# CH564 register map
Vendor: WCH Ltd.; File version: 1.0
Registers are 8-bit, read-write, reset 0x0 unless marked. A register's access mark holds for its fields unless they carry their own. Offsets are from the block's base; [hi:lo] are bit positions.

## SPI1
Base 0x4040C800
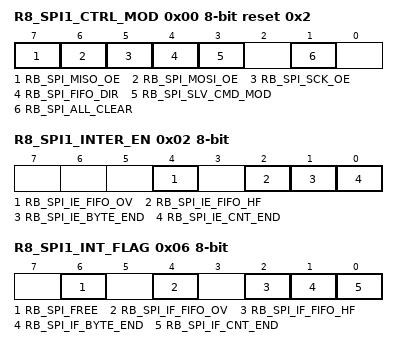
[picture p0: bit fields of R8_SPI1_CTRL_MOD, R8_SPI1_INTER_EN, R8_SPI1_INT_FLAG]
0x00 R8_SPI1_CTRL_MOD reset 0x2 — SPI1 mode control
  [7] RB_SPI_MISO_OE — SPI 2 wire or 3 wire SPI mode configuration bits
  [6] RB_SPI_MOSI_OE — SPI MOSI output enable
  [5] RB_SPI_SCK_OE — SPI SCK output enable
  [4] RB_SPI_FIFO_DIR — SPI FIFO direction
  [3] RB_SPI_SLV_CMD_MOD — SPI slave command mode
  [1] RB_SPI_ALL_CLEAR — force clear SPI FIFO and count
0x01 R8_SPI1_CTRL_DMA — SPI1 DMA control
  [7] RB_SPI_HS_HOST — High speed host receive mode control bit
0x02 R8_SPI1_INTER_EN — SPI1 interrupt enable
  [4] RB_SPI_IE_FIFO_OV — enable interrupt for SPI FIFO overflow
  [2] RB_SPI_IE_FIFO_HF — enable interrupt for SPI FIFO half
  [1] RB_SPI_IE_BYTE_END — enable interrupt for SPI single byte exchanged
  [0] RB_SPI_IE_CNT_END — enable interrupt for SPI total byte count end
0x03 R8_SPI1_CLOCK_DIV reset 0x2 — SPI1 master clock divisor
  [7:0] SPI1_CLOCK_DIV — master clock divisor
0x04 R8_SPI1_BUFFER — SPI1 data buffer
  [7:0] SPI1_BUFFER — SPI data buffer
0x05 R8_SPI1_RUN_FLAG ro — SPI1 work flag
  [5] RB_SPI_FIFO_READY — SPI FIFO ready status
0x06 R8_SPI1_INT_FLAG — SPI1 interrupt flag
  [6] RB_SPI_FREE — current SPI free status
  [4] RB_SPI_IF_FIFO_OV — interrupt flag for SPI FIFO overflow
  [2] RB_SPI_IF_FIFO_HF — interrupt flag for SPI FIFO half
  [1] RB_SPI_IF_BYTE_END — interrupt flag for SPI byte exchanged
  [0] RB_SPI_IF_CNT_END — interrupt flag for SPI total byte count end
0x07 R8_SPI1_FIFO_COUNT ro — SPI1 FIFO count status
  [7:0] SPI1_FIFO_COUNT — SPI FIFO count status
0x0C R16_SPI1_TOTAL_CNT 16-bit — SPI1 total byte count, only low 12 bit
  [11:0] SPI1_TOTAL_CNT — SPI total byte count, only low 12 bit
0x10 R8_SPI1_FIFO read-only/write-only — SPI1 FIFO register
  [7:0] SPI1_FIFO — SPI FIFO register
0x13 R8_SPI1_FIFO_COUNT1 ro — SPI1 FIFO count status
  [7:0] R8_SPI1_FIFO_COUNT1 — SPI FIFO count statu

## I2C1 — Inter integrated circuit
Base 0x4040F000
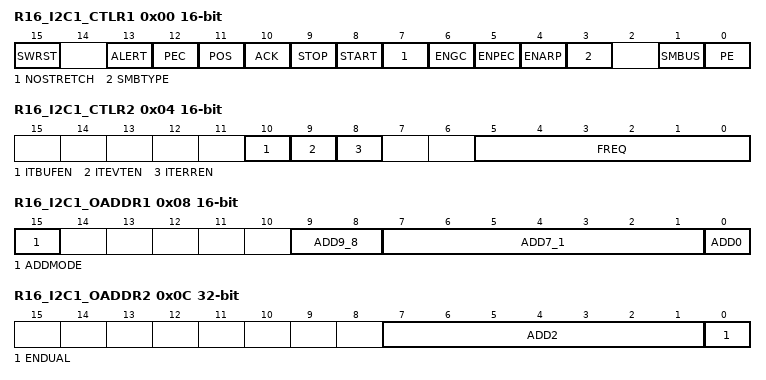
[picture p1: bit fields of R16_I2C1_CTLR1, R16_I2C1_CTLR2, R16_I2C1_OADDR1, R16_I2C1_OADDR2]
0x00 R16_I2C1_CTLR1 16-bit — Control register 1
  [15] SWRST — Software reset
  [13] ALERT — SMBus alert
  [12] PEC — Packet error checking
  [11] POS — Acknowledge_PEC Position (for data reception)
  [10] ACK — Acknowledge enable
  [9] STOP — Stop generation
  [8] START — Start generation
  [7] NOSTRETCH — Clock stretching disable (Slave mode)
  [6] ENGC — General call enable
  [5] ENPEC — PEC enable
  [4] ENARP — ARP enable
  [3] SMBTYPE — SMBus type
  [1] SMBUS — SMBus mode
  [0] PE — Peripheral enable
0x04 R16_I2C1_CTLR2 16-bit — Control register 2
  [10] ITBUFEN — Buffer interrupt enable
  [9] ITEVTEN — Event interrupt enable
  [8] ITERREN — Error interrupt enable
  [5:0] FREQ — Peripheral clock frequency
0x08 R16_I2C1_OADDR1 16-bit — Own address register 1
  [15] ADDMODE — Addressing mode (slave mode)
  [9:8] ADD9_8 — Interface address
  [7:1] ADD7_1 — Interface address
  [0] ADD0 — Interface address
0x0C R16_I2C1_OADDR2 32-bit — Own address register 2
  [7:1] ADD2 — Interface address
  [0] ENDUAL — Dual addressing mode enable
0x10 R16_I2C1_DATAR 32-bit — Data register
  [7:0] DR — 8-bit data register
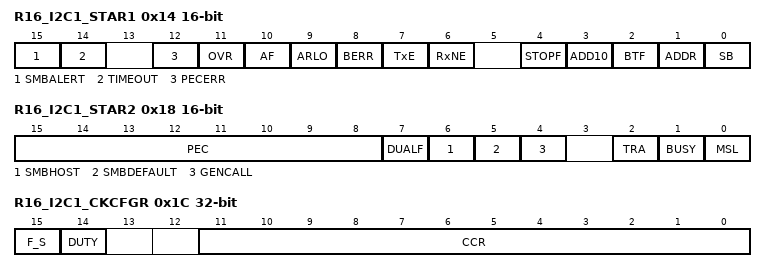
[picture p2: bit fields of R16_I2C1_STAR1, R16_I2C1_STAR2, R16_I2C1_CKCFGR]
0x14 R16_I2C1_STAR1 16-bit access per field — Status register 1
  [15] SMBALERT rw — SMBus alert
  [14] TIMEOUT rw — Timeout or Tlow error
  [12] PECERR rw — PEC Error in reception
  [11] OVR rw — Overrun_Underrun
  [10] AF rw — Acknowledge failure
  [9] ARLO rw — Arbitration lost (master mode)
  [8] BERR rw — Bus error
  [7] TxE ro — Data register empty (transmitters)
  [6] RxNE ro — Data register not empty (receivers)
  [4] STOPF ro — Stop detection (slave mode)
  [3] ADD10 ro — 10-bit header sent (Master mode)
  [2] BTF ro — Byte transfer finished
  [1] ADDR ro — Address sent (master mode)/matched (slave mode)
  [0] SB ro — Start bit (Master mode)
0x18 R16_I2C1_STAR2 16-bit ro — Status register 2
  [15:8] PEC — acket error checking register
  [7] DUALF — Dual flag (Slave mode)
  [6] SMBHOST — SMBus host header (Slave mode)
  [5] SMBDEFAULT — SMBus device default address (Slave mode)
  [4] GENCALL — General call address (Slave mode)
  [2] TRA — Transmitter/receiver
  [1] BUSY — Bus busy
  [0] MSL — Master_slave
0x1C R16_I2C1_CKCFGR 32-bit — Clock control register
  [15] F_S — I2C master mode selection
  [14] DUTY — Fast mode duty cycle
  [11:0] CCR — Clock control register in Fast_Standard mode (Master mode)
0x20 R16_I2C1_RTR 16-bit reset 0x2 — Raise time register
  [5:0] TRISE — Maximum rise time in Fast_Standard mode (Master mode)
